# S32K118 register map
Vendor: NXP; Series: S32K; File version: 1.6
CPU: CM0PLUS r0p0, little endian, MPU, FPU, 2 interrupt priority bits
Registers are 32-bit, read-write, reset 0x0 unless marked. A register's access mark holds for its fields unless they carry their own. Offsets are from the block's base; [hi:lo] are bit positions; {n}, {i} and the like mark numbered series; 'fields as' and 'values as' point back to an identical list.

## MPU — Memory protection unit
Base 0x4000D000; register names take the prefix MPU_
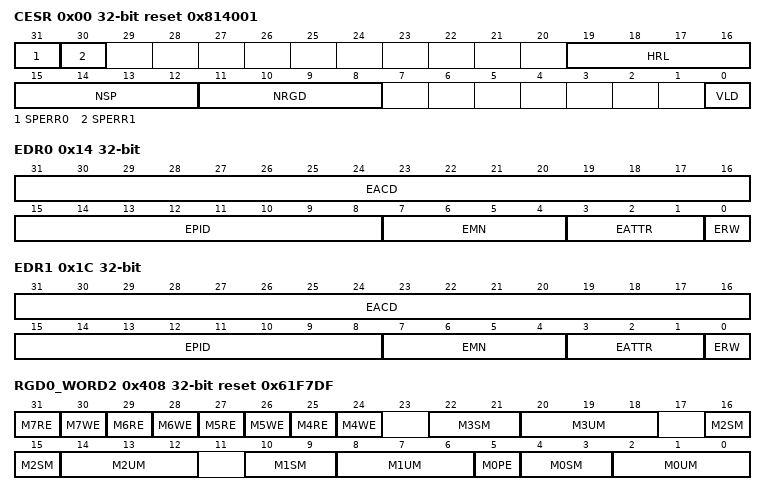
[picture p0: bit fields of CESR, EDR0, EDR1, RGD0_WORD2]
0x00 CESR reset 0x814001 — Control/Error Status Register
  [31] SPERR0 — Slave Port 0 Error
    0=No error has occurred for slave port 0; 1=An error has occurred for slave port 0
  [30] SPERR1 — Slave Port 1 Error
    0=No error has occurred for slave port 1; 1=An error has occurred for slave port 1
  [19:16] HRL ro — Hardware Revision Level
  [15:12] NSP ro — Number Of Slave Ports
  [11:8] NRGD ro — Number Of Region Descriptors
    0=8 region descriptors; 1=12 region descriptors; 2=16 region descriptors
  [0] VLD — Valid
    0=MPU is disabled. All accesses from all bus masters are allowed.; 1=MPU is enabled
0x10 EAR0 ro — Error Address Register, slave port 0
  [31:0] EADDR — Error Address
0x14 EDR0 ro — Error Detail Register, slave port 0
  [31:16] EACD — Error Access Control Detail
  [15:8] EPID — Error Process Identification
  [7:4] EMN — Error Master Number
  [3:1] EATTR — Error Attributes
    0=User mode, instruction access; 1=User mode, data access; 2=Supervisor mode, instruction access; 3=Supervisor mode, data access
  [0] ERW — Error Read/Write
    0=Read; 1=Write
0x18 EAR1 ro — Error Address Register, slave port 1
  [31:0] EADDR — Error Address
0x1C EDR1 ro — Error Detail Register, slave port 1
  fields as EDR0
{0x400+0x10*i} RGD{i}_WORD0 (i=0..7) — Region Descriptor {i}, Word 0
  [31:5] SRTADDR — Start Address
0x404 RGD0_WORD1 reset 0xFFFFFFFF — Region Descriptor 0, Word 1
  [31:5] ENDADDR — End Address
0x408 RGD0_WORD2 reset 0x61F7DF — Region Descriptor 0, Word 2
  [2n+17] M{n}RE (n=4..7) — Bus Master {n} Read Enable
    0=Bus master {n} reads terminate with an access error and the read is not performed; 1=Bus master {n} reads allowed
  [2n+16] M{n}WE (n=4..7) — Bus Master {n} Write Enable
    0=Bus master {n} writes terminate with an access error and the write is not performed; 1=Bus master {n} writes allowed
  [6n+4:6n+3] M{n}SM (n=0..3) — Bus Master {n} Supervisor Mode Access Control
    0=r/w/x; read, write and execute allowed; 1=r/x; read and execute allowed, but no write; 2=r/w; read and write allowed, but no execute; 3=Same as User mode defined in M{n}UM
  [20:18] M3UM — Bus Master 3 User Mode Access Control
  [14:12] M2UM — Bus Master 2 User Mode Access control
  [8:6] M1UM — Bus Master 1 User Mode Access Control
  [5] M0PE — Bus Master 0 Process Identifier enable
    0=Do not include the process identifier in the evaluation; 1=Include the process identifier and mask (RGDn.RGDAAC) in the region hit evaluation
  [2:0] M0UM — Bus Master 0 User Mode Access Control
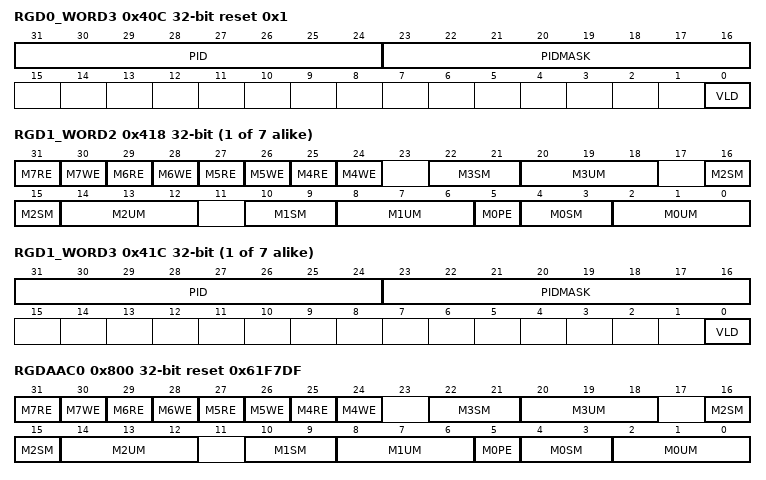
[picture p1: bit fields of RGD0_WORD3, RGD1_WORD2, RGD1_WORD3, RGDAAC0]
0x40C RGD0_WORD3 reset 0x1 — Region Descriptor 0, Word 3
  [31:24] PID — Process Identifier
  [23:16] PIDMASK — Process Identifier Mask
  [0] VLD — Valid
    0=Region descriptor is invalid; 1=Region descriptor is valid
{0x404+0x10*i} RGD{i}_WORD1 reset 0x1F (i=1..7) — Region Descriptor {i}, Word 1
  [31:5] ENDADDR — End Address
{0x408+0x10*i} RGD{i}_WORD2 (i=1..7) — Region Descriptor {i}, Word 2
  fields as RGD0_WORD2
{0x40C+0x10*i} RGD{i}_WORD3 (i=1..7) — Region Descriptor {i}, Word 3
  fields as RGD0_WORD3
0x800 RGDAAC0 reset 0x61F7DF — Region Descriptor Alternate Access Control 0
  [2n+17] M{n}RE (n=4..7) — Bus Master {n} Read Enable
    values as RGD0_WORD2.M4RE
  [2n+16] M{n}WE (n=4..7) — Bus Master {n} Write Enable
    values as RGD0_WORD2.M4WE
  [6n+4:6n+3] M{n}SM (n=0..3) — Bus Master {n} Supervisor Mode Access Control
    values as RGD0_WORD2.M0SM
  [6n+2:6n] M{n}UM (n=0..3) — Bus Master {n} User Mode Access Control
  [5] M0PE — Bus Master 0 Process Identifier Enable
    values as RGD0_WORD2.M0PE
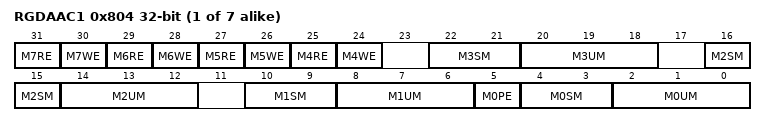
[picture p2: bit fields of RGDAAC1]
{0x800+4i} RGDAAC{i} (i=1..7) — Region Descriptor Alternate Access Control {i}
  fields as RGDAAC0
